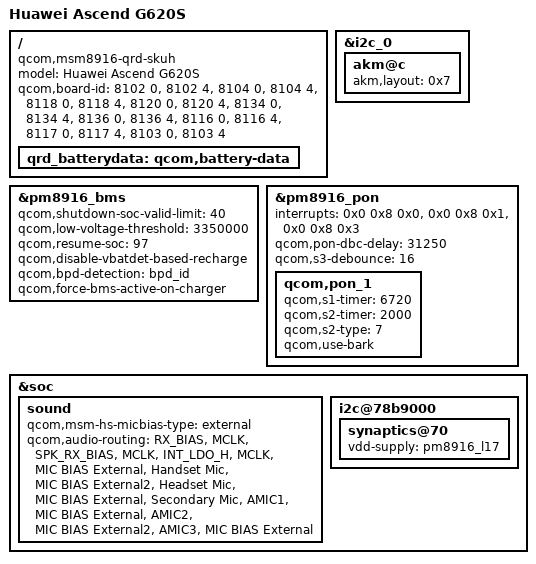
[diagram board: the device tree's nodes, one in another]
/* Copyright (c) 2014, The Linux Foundation. All rights reserved.
 * Copyright (c) 2015, Rudolf Tammekivi
 *
 * This program is free software; you can redistribute it and/or modify
 * it under the terms of the GNU General Public License version 2 and
 * only version 2 as published by the Free Software Foundation.
 *
 * This program is distributed in the hope that it will be useful,
 * but WITHOUT ANY WARRANTY; without even the implied warranty of
 * MERCHANTABILITY or FITNESS FOR A PARTICULAR PURPOSE.  See the
 * GNU General Public License for more details.
 */

/* Based on msm8916-qrd-skuh.dts */

/dts-v1/;

#include "msm8916-qrd-skuh.dtsi"
#include "msm8916-memory.dtsi"

#include "hw-panel-boe-hx8394d-5-720p-video.dtsi"
#include "hw-panel-boe-nt35521-5-720p-video.dtsi"
#include "hw-panel-cmi-otm1283a-5-720p-video.dtsi"
#include "hw-panel-tianma-otm1283a-5-720p-video.dtsi"

/ {
	model = "Huawei Ascend G620S";
	compatible = "qcom,msm8916-qrd-skuh", "qcom,msm8916-qrd", "qcom,msm8916", "qcom,qrd";
	qcom,board-id =	<8102 0>, <8102 4>,
			<8104 0>, <8104 4>,
			<8118 0>, <8118 4>,
			<8120 0>, <8120 4>,
			<8134 0>, <8134 4>,
			<8136 0>, <8136 4>,
			<8116 0>, <8116 4>,
			<8117 0>, <8117 4>,
			<8103 0>, <8103 4>;

	qrd_batterydata: qcom,battery-data {
		#include "HB3742A0EBC_ATL_SWD-4v35-2000mah.dtsi"
		#include "HB3742A0EBC_LS_LS-4v35-2000mah.dtsi"
		#include "HB3742A0EBC_SONY_SCUD-4v35-2000mah.dtsi"
	};
};

&i2c_0 { /* BLSP1 QUP2 */
	akm@c {
		akm,layout = <0x7>;
	};
};

&pm8916_bms {
	qcom,shutdown-soc-valid-limit = <40>;
	qcom,low-voltage-threshold = <3350000>;
	qcom,resume-soc = <97>;
	qcom,disable-vbatdet-based-recharge;
	qcom,bpd-detection = "bpd_id";
	qcom,force-bms-active-on-charger;
};

&pm8916_pon {
	interrupts = <0x0 0x8 0x0>,
		     <0x0 0x8 0x1>,
		     <0x0 0x8 0x3>;
	interrupt-names = "kpdpwr", "resin", "kpdpwr-bark";
	qcom,pon-dbc-delay = <31250>;
	qcom,s3-debounce = <16>;

	qcom,pon_1 {
		qcom,s1-timer = <6720>;
		qcom,s2-timer = <2000>;
		qcom,s2-type = <7>;
		qcom,use-bark;
	};
};

&soc {

	sound {
		qcom,msm-hs-micbias-type = "external";
		qcom,audio-routing =
				"RX_BIAS", "MCLK",
				"SPK_RX_BIAS", "MCLK",
				"INT_LDO_H", "MCLK",
				"MIC BIAS External", "Handset Mic",
				"MIC BIAS External2", "Headset Mic",
				"MIC BIAS External", "Secondary Mic",
				"AMIC1", "MIC BIAS External",
				"AMIC2", "MIC BIAS External2",
				"AMIC3", "MIC BIAS External";
	};

	i2c@78b9000 { /* BLSP1 QUP5 */
		synaptics@70 {
			vdd-supply = <&pm8916_l17>;
		};
	};
};
